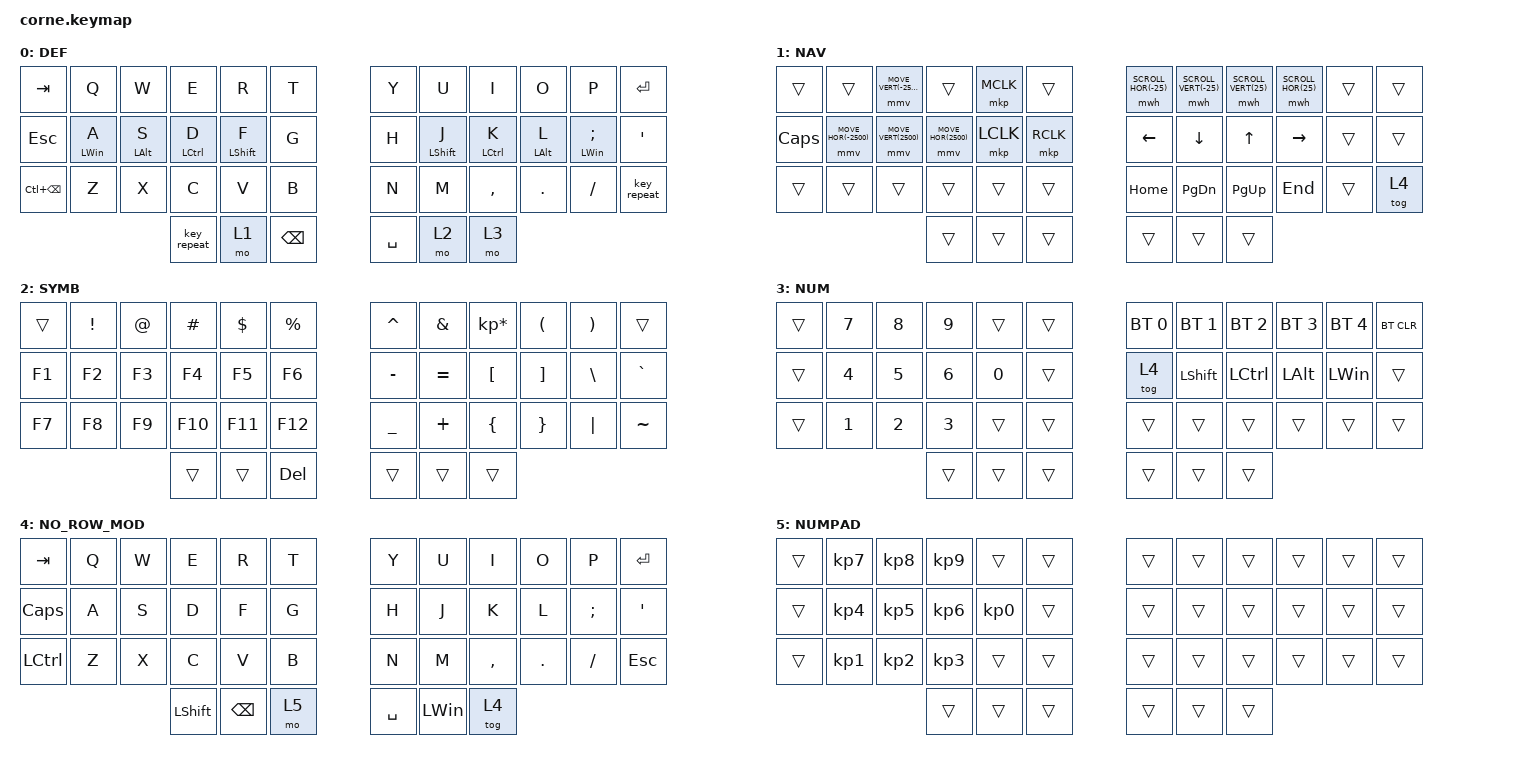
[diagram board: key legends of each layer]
/*
 * Copyright (c) 2020 The ZMK Contributors
 *
 * SPDX-License-Identifier: MIT
 */


#include <behaviors.dtsi>
#include <dt-bindings/zmk/keys.h>
#include <dt-bindings/zmk/bt.h>
#include <dt-bindings/zmk/outputs.h>
#include <dt-bindings/zmk/mouse.h>
#include <dt-bindings/zmk/ext_power.h>

&mmv {    
     time-to-max-speed-ms = <500>;
     acceleration-exponent=<1>;
};
&mwh {    
    time-to-max-speed-ms = <4000>;
    acceleration-exponent=<0>;
}; 


/ {
    behaviors {
        hm: homerow_mods {
            compatible = "zmk,behavior-hold-tap";
            label = "HOMEROW_MODS";
            #binding-cells = <2>;
            tapping-term-ms = <150>;
            quick-tap-ms = <0>;
            flavor = "tap-preferred";
            bindings =
                <&kp>,
                <&kp>;
        };
    };

    keymap {
        compatible = "zmk,keymap";

        DEF {
            bindings = <
           &kp TAB           &kp Q           &kp W               &kp E         &kp R          &kp T      &kp Y             &kp U               &kp I           &kp O                   &kp P     &kp ENTER
           &kp ESC  &hm LEFT_WIN A  &hm LEFT_ALT S  &hm LEFT_CONTROL D  &hm LSHIFT F          &kp G      &kp H  &hm LEFT_SHIFT J  &hm LEFT_CONTROL K  &hm LEFT_ALT L  &hm LEFT_WIN SEMICOLON       &kp SQT
 &kp LC(BACKSPACE)           &kp Z           &kp X               &kp C         &kp V          &kp B      &kp N             &kp M           &kp COMMA         &kp DOT                &kp FSLH   &key_repeat
                                                           &key_repeat         &mo 1  &kp BACKSPACE  &kp SPACE             &mo 2               &mo 3
            >;
        };

        NAV {
            bindings = <
 &trans                  &trans   &mmv MOVE_VERT(-2500)               &trans  &mkp MCLK     &trans  &mwh SCROLL_HOR(-25)  &mwh SCROLL_VERT(-25) &mwh SCROLL_VERT(25) &mwh SCROLL_HOR(25)  &trans  &trans
 &kp CAPS  &mmv MOVE_HOR(-2500)    &mmv MOVE_VERT(2500)  &mmv MOVE_HOR(2500)  &mkp LCLK  &mkp RCLK              &kp LEFT               &kp DOWN               &kp UP           &kp RIGHT  &trans  &trans
 &trans                  &trans                 &trans                &trans     &trans     &trans              &kp HOME          &kp PAGE_DOWN          &kp PAGE_UP             &kp END  &trans  &tog 4
                                                                    &trans     &trans     &trans                &trans                 &trans               &trans
            >;
        };

        SYMB {
            bindings = <
 &trans  &kp EXCL  &kp AT  &kp HASH  &kp DLLR   &kp PRCNT  &kp CARET   &kp AMPS  &kp KP_MULTIPLY  &kp LPAR  &kp RPAR  &trans
 &kp F1    &kp F2  &kp F3    &kp F4    &kp F5      &kp F6  &kp MINUS  &kp EQUAL         &kp LBKT  &kp RBKT  &kp BSLH  &kp GRAVE
 &kp F7    &kp F8  &kp F9   &kp F10   &kp F11     &kp F12  &kp UNDER   &kp PLUS         &kp LBRC  &kp RBRC  &kp PIPE  &kp TILDE
                             &trans    &trans  &kp DELETE     &trans     &trans           &trans
            >;
        };

        NUM {
            bindings = <
 &trans  &kp NUMBER_7  &kp NUMBER_8  &kp NUMBER_9  &trans          &trans     &bt BT_SEL 0    &bt BT_SEL 1      &bt BT_SEL 2  &bt BT_SEL 3  &bt BT_SEL 4  &bt BT_CLR
 &trans  &kp NUMBER_4  &kp NUMBER_5  &kp NUMBER_6  &kp NUMBER_0    &trans           &tog 4  &kp LEFT_SHIFT  &kp LEFT_CONTROL  &kp LEFT_ALT  &kp LEFT_WIN    &trans
 &trans  &kp NUMBER_1  &kp NUMBER_2  &kp NUMBER_3  &trans          &trans           &trans          &trans            &trans        &trans        &trans    &trans
                                     &trans        &trans          &trans           &trans          &trans            &trans
            >;
        };
        
        NO_ROW_MOD {
            bindings = <
   &kp TAB   &kp Q   &kp W       &kp E   &kp R          &kp T      &kp Y         &kp U      &kp I    &kp O          &kp P  &kp ENTER
  &kp CAPS   &kp A   &kp S       &kp D   &kp F          &kp G      &kp H         &kp J      &kp K    &kp L  &kp SEMICOLON    &kp SQT
 &kp LCTRL   &kp Z   &kp X       &kp C   &kp V          &kp B      &kp N         &kp M  &kp COMMA  &kp DOT      &kp SLASH    &kp ESC
                            &kp LSHIFT   &kp BACKSPACE  &mo 5      &kp SPACE  &kp LEFT_WIN     &tog 4
            >;
        };
        
        NUMPAD {
            bindings = <
 &trans  &kp KP_NUMBER_7  &kp KP_NUMBER_8  &kp KP_NUMBER_9           &trans  &trans  &trans  &trans  &trans  &trans  &trans  &trans
 &trans  &kp KP_NUMBER_4  &kp KP_NUMBER_5  &kp KP_NUMBER_6  &kp KP_NUMBER_0  &trans  &trans  &trans  &trans  &trans  &trans  &trans
 &trans  &kp KP_NUMBER_1  &kp KP_NUMBER_2  &kp KP_NUMBER_3           &trans  &trans  &trans  &trans  &trans  &trans  &trans  &trans
                                                    &trans           &trans  &trans  &trans  &trans  &trans
            >;
        };
       
    };
};
